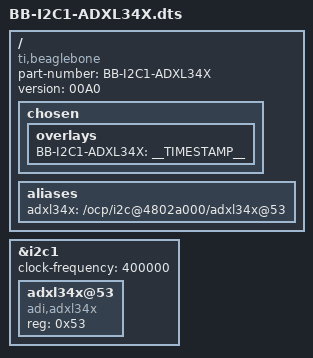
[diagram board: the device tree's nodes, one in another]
/*
 * Copyright (C) 2018 Seeed Studio
 * Peter Yang <turmary@126.com>
 *
 * MIT License
 *
 */
/dts-v1/;
/plugin/;

/ {
	compatible = "ti,beaglebone", "ti,beaglebone-black", "ti,beaglebone-green";

	/* identification */
	part-number = "BB-I2C1-ADXL34X";
	version = "00A0";

	fragment@0 {
		target-path="/";
		__overlay__ {
			chosen {
				overlays {
					BB-I2C1-ADXL34X = __TIMESTAMP__;
				};
			};

			aliases {
				/* SLOT I2C1 */
				adxl34x = "/ocp/i2c@4802a000/adxl34x@53";
				/* SLOT I2C2 */
				/*
				adxl34x = "/ocp/i2c@4819c000/adxl34x@53";
				*/
			};
		};
	};

	fragment@1 {
		/* SLOT I2C1 */
		/*
		target = <&i2c1>;
		*/
		/* SLOT I2C2 */
		target = <&i2c1>;

		__overlay__ {
			status = "okay";

			clock-frequency = <400000>;

			#address-cells = <1>;
			#size-cells = <0>;

			adxl34x@53 {
				compatible = "adi,adxl34x";
				reg = <0x53>;
				status = "okay";
			};
		};
	};
};

